# STM32U073 register map
File version: 0.2
CPU: CM0+ r0p1, little endian, MPU, no FPU, 4 interrupt priority bits
Registers are 32-bit, read-write, reset 0x0 unless marked. A register's access mark holds for its fields unless they carry their own. Offsets are from the block's base; [hi:lo] are bit positions; 'fields as' and 'values as' point back to an identical list.

## COMP1 — COMP address block description
Base 0x40010200
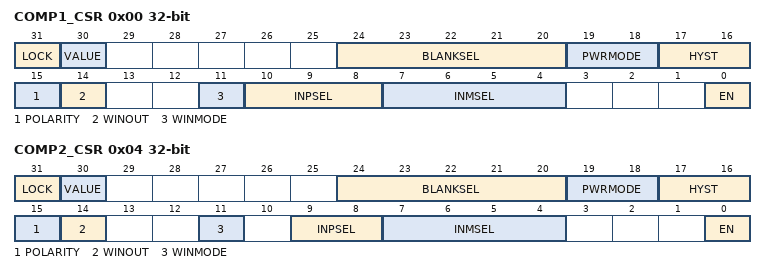
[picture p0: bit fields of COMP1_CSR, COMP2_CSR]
0x00 COMP1_CSR access per field — Comparator 1 control and status register
  [31] LOCK rw — COMP_CSR register lock This bit is set by software and cleared by a system reset. It locks the comparator 3 control bits. When locked, all register bits are read-only.
    0=Not locked; 1=Locked
  [30] VALUE ro — Comparator 1 output status This bit is read-only. It reflects the level of the comparator 1 output after the polarity selector and blanking, as indicated in Figure163.
  [24:20] BLANKSEL rw — Comparator 1 blanking source selector This bitfield is controlled by software (if not locked). It selects the blanking source: Others: Reserved, must not be used
    0=No blanking; 1=TIM1 OC4 enabled as blanking source; 2=TIM1 OC5 enabled as blanking source; 4=TIM2 OC3 enabled as blanking source; 8=TIM3 OC3 enabled as blanking source; 16=TIM15 OC2 enabled as blanking source
  [19:18] PWRMODE rw — Comparator 1 power mode selector This bitfield is controlled by software (if not locked). It selects the power consumption and as a consequence the speed of the comparator 1:
    0=High speed/high power; 1=Medium speed/medium power; 2=Medium speed/medium power; 3=Low speed/low power
  [17:16] HYST rw — Comparator 1 hysteresis selector This bitfield is controlled by software (if not locked). It selects the hysteresis of the comparator 1:
    0=No hysteresis; 1=Low hysteresis; 2=Medium hysteresis; 3=High hysteresis
  [15] POLARITY rw — Comparator 1 polarity selector This bit is controlled by software (if not locked). It selects the comparator 1 output polarity:
    0=Non-inverted; 1=Inverted
  [14] WINOUT rw — Comparator 1 output selector This bit is controlled by software (if not locked). It selects the comparator 1 output:
    0=COMP_VALUE; 1=COMP_VALUE XOR COMP_VALUE (required for window mode, see Figure164)
  [11] WINMODE rw — Comparator 1 noninverting input selector for window mode This bit is controlled by software (if not locked). It selects the signal for COMP_INP input of the comparator 1:
    0=Signal selected with INPSEL[2:0] bitfield of this register; 1=COMP_INP signal of the comparator 2 (required for window mode, see Figure164)
  [10:8] INPSEL rw — Comparator 1 signal selector for noninverting input This bitfield is controlled by software (if not locked). It selects the signal for the noninverting input COMP_INP of the comparator 1 (also see the WINMODE bit): Refer to Table175: COMP1 noninverting input assignment.
  [7:4] INMSEL rw — Comparator 1 signal selector for inverting input INM This bitfield is controlled by software (if not locked). It selects the signal for the inverting input COMP_INM of the comparator 1: Refer to Table176: COMP1 inverting input assignment.
  [0] EN rw — Comparator 1 enable bit This bit is controlled by software (if not locked). It enables the comparator 1:
    0=Disable; 1=Enable
0x04 COMP2_CSR access per field — Comparator 2 control and status register
  [31] LOCK rw — COMP_CSR register lock This bit is set by software and cleared by a system reset. It locks the comparator 3 control bits. When locked, all register bits are read-only.
    0=Not locked; 1=Locked
  [30] VALUE ro — Comparator 2 output status This bit is read-only. It reflects the level of the comparator 2 output after the polarity selector and blanking, as indicated in Figure163.
  [24:20] BLANKSEL rw — Comparator 2 blanking source selector This bitfield is controlled by software (if not locked). It selects the blanking source: Others: Reserved, must not be used
    values as COMP1_CSR.BLANKSEL
  [19:18] PWRMODE rw — Comparator 2 power mode selector This bitfield is controlled by software (if not locked). It selects the power consumption and as a consequence the speed of the comparator 2:
    values as COMP1_CSR.PWRMODE
  [17:16] HYST rw — Comparator 2 hysteresis selector This bitfield is controlled by software (if not locked). It selects the hysteresis of the comparator 2:
    values as COMP1_CSR.HYST
  [15] POLARITY rw — Comparator 2 polarity selector This bit is controlled by software (if not locked). It selects the comparator 2 output polarity:
    0=Non-inverted; 1=Inverted
  [14] WINOUT rw — Comparator 2 output selector This bit is controlled by software (if not locked). It selects the comparator 2 output:
    values as COMP1_CSR.WINOUT
  [11] WINMODE rw — Comparator 2 noninverting input selector for window mode This bit is controlled by software (if not locked). It selects the signal for COMP_INP input of the comparator 2:
    0=Signal selected with INPSEL[1:0] bitfield of this register; 1=COMP_INP signal of the comparator 1 (required for window mode, see Figure164)
  [9:8] INPSEL rw — Comparator 2 signal selector for noninverting input This bitfield is controlled by software (if not locked). It selects the signal for the noninverting input COMP_INP of the comparator 2 (also see the WINMODE bit): Refer to Table177: COMP2 noninverting input assignment.
  [7:4] INMSEL rw — Comparator 2 signal selector for inverting input INM This bitfield is controlled by software (if not locked). It selects the signal for the inverting input COMP_INM of the comparator 2: Refer to Table178: COMP2 inverting input assignment.
  [0] EN rw — Comparator 2 enable bit This bit is controlled by software (if not locked). It enables the comparator 2:
    0=Disable; 1=Enable

## Notices in the file
Copyright (c) 2024 STMicroelectronics.
SPDX-License-Identifier: Apache-2.0
Licensed under the Apache License, Version 2.0 (the "License");
you may not use this file except in compliance with the License.
You may obtain a copy of the License at
http://www.apache.org/licenses/LICENSE-2.0
Unless required by applicable law or agreed to in writing, software
distributed under the License is distributed on an "AS IS" BASIS,
WITHOUT WARRANTIES OR CONDITIONS OF ANY KIND, either express or implied.
See the License for the specific language governing permissions and
limitations under the License.
